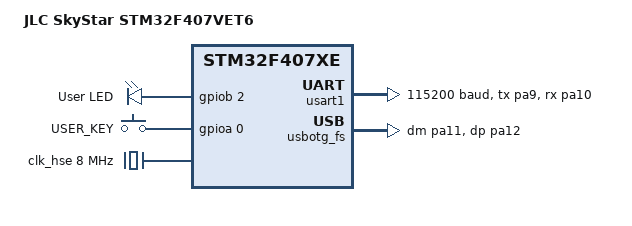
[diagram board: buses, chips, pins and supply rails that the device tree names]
// SPDX-License-Identifier: Apache-2.0
/*
 * Copyright (c) 2026, Liu Changjie <liucj1228@outlook.com>
 */

/dts-v1/;

#include <st/f4/stm32f407Xe.dtsi>
#include <st/f4/stm32f407v(e-g)tx-pinctrl.dtsi>
#include <zephyr/dt-bindings/input/input-event-codes.h>

/ {
	model = "JLC SkyStar STM32F407VET6";

	chosen {
		zephyr,console = &usart1;
		zephyr,shell-uart = &usart1;
		zephyr,sram = &sram0;
		zephyr,flash = &flash0;
		zephyr,dtcm = &ccm0;
	};

	leds {
		compatible = "gpio-leds";

		led0: led_0 {
			gpios = <&gpiob 2 GPIO_ACTIVE_HIGH>;
			label = "User LED";
		};
	};

	gpio_keys {
		compatible = "gpio-keys";

		user_key: user_key {
			label = "USER_KEY";
			gpios = <&gpioa 0 GPIO_ACTIVE_HIGH>;
			zephyr,code = <INPUT_KEY_0>;
		};
	};

	aliases {
		led0 = &led0;
		sw0 = &user_key;
	};
};

&clk_lsi {
	status = "okay";
};

&clk_hse {
	clock-frequency = <DT_FREQ_M(8)>;
	status = "okay";
};

&pll {
	div-m = <8>;
	mul-n = <336>;
	div-p = <2>;
	div-q = <7>;
	clocks = <&clk_hse>;
	status = "okay";
};

&rcc {
	clocks = <&pll>;
	clock-frequency = <DT_FREQ_M(168)>;
	ahb-prescaler = <1>;
	apb1-prescaler = <4>;
	apb2-prescaler = <2>;
};

&usart1 {
	pinctrl-0 = <&usart1_tx_pa9 &usart1_rx_pa10>;
	pinctrl-names = "default";
	current-speed = <115200>;
	status = "okay";
};

zephyr_udc0: &usbotg_fs {
	pinctrl-0 = <&usb_otg_fs_dm_pa11 &usb_otg_fs_dp_pa12>;
	pinctrl-names = "default";
	status = "okay";
};
